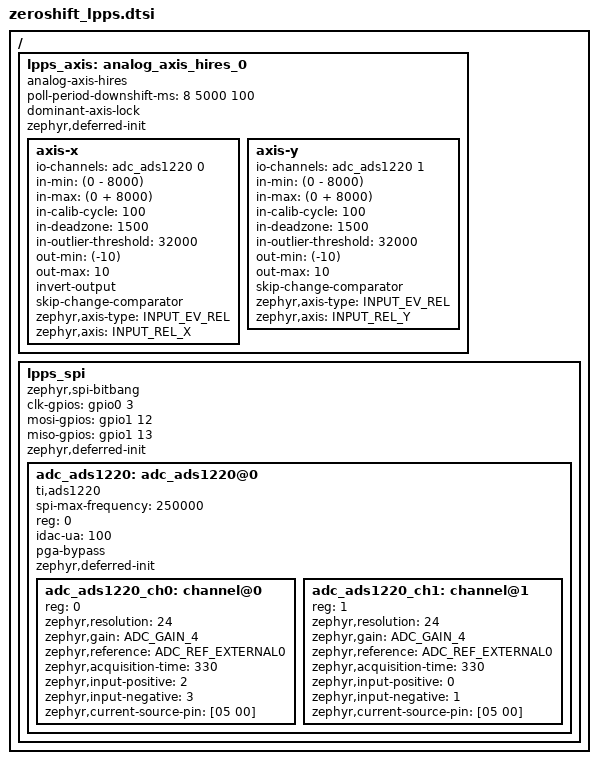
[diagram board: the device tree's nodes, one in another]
#include <dt-bindings/gpio/gpio.h>
#include <dt-bindings/spi/spi.h>
#include <zephyr/dt-bindings/input/input-event-codes.h>

/ {
    lpps_axis: analog_axis_hires_0 {
        compatible = "analog-axis-hires";
        status = "okay";
        poll-period-downshift-ms = <8 5000 100>;
        dominant-axis-lock;

        axis-x {
            status = "okay";
            io-channels = <&adc_ads1220 0>;
            in-min = <(0 - 8000)>;
            in-max = <(0 + 8000)>;
            in-calib-cycle = <100>;
            in-deadzone = <1500>;
            in-outlier-threshold = <32000>;
            out-min = <(-10)>;
            out-max = <10>;
            invert-output;
            skip-change-comparator;
            zephyr,axis-type = <INPUT_EV_REL>;
            zephyr,axis = <INPUT_REL_X>;
        };

        axis-y {
            status = "okay";
            io-channels = <&adc_ads1220 1>;
            in-min = <(0 - 8000)>;
            in-max = <(0 + 8000)>;
            in-calib-cycle = <100>;
            in-deadzone = <1500>;
            in-outlier-threshold = <32000>;
            out-min = <(-10)>;
            out-max = <10>;
            skip-change-comparator;
            zephyr,axis-type = <INPUT_EV_REL>;
            zephyr,axis = <INPUT_REL_Y>;
        };
    };

    lpps_spi: lpps_spi {
        compatible = "zephyr,spi-bitbang";
        status = "okay";
        #address-cells = <1>;
        #size-cells = <0>;
        clk-gpios = <&gpio0 3 GPIO_ACTIVE_HIGH>;
        mosi-gpios = <&gpio1 12 GPIO_ACTIVE_HIGH>;
        miso-gpios = <&gpio1 13 GPIO_ACTIVE_HIGH>;

        adc_ads1220: adc_ads1220@0 {
            compatible = "ti,ads1220";
            status = "okay";
            spi-max-frequency = <250000>;
            reg = <0>;
            idac-ua = <100>;
            pga-bypass;
            #io-channel-cells = <1>;
            #address-cells = <1>;
            #size-cells = <0>;

            adc_ads1220_ch0: channel@0 {
                reg = <0>;
                zephyr,resolution = <24>;
                zephyr,gain = "ADC_GAIN_4";
                zephyr,reference = "ADC_REF_EXTERNAL0";
                zephyr,acquisition-time = <330>;
                zephyr,input-positive = <2>;
                zephyr,input-negative = <3>;
                zephyr,current-source-pin = [05 00];
            };

            adc_ads1220_ch1: channel@1 {
                reg = <1>;
                zephyr,resolution = <24>;
                zephyr,gain = "ADC_GAIN_4";
                zephyr,reference = "ADC_REF_EXTERNAL0";
                zephyr,acquisition-time = <330>;
                zephyr,input-positive = <0>;
                zephyr,input-negative = <1>;
                zephyr,current-source-pin = [05 00];
            };
        };
    };
};

&lpps_axis { zephyr,deferred-init; };
&adc_ads1220 { zephyr,deferred-init; };
&lpps_spi { zephyr,deferred-init; };
